# MLDR187 register map
File version: 1.3
CPU: MLDR178, little endian
Registers are 32-bit, read-write, no defined reset value unless marked. A register's access mark holds for its fields unless they carry their own. Offsets are from the block's base; [hi:lo] are bit positions; {n}, {i} and the like mark numbered series.

## TIMER1 — TIMER1 description
Base 0x40070000
Same registers: TIMER2 0x40078000, TIMER3 0x400D8000, TIMER4 0x400E0000
0x00 CNT — CNT description
0x04 PSG — PSG description
  [15:0] PSG
0x08 ARR — ARR description
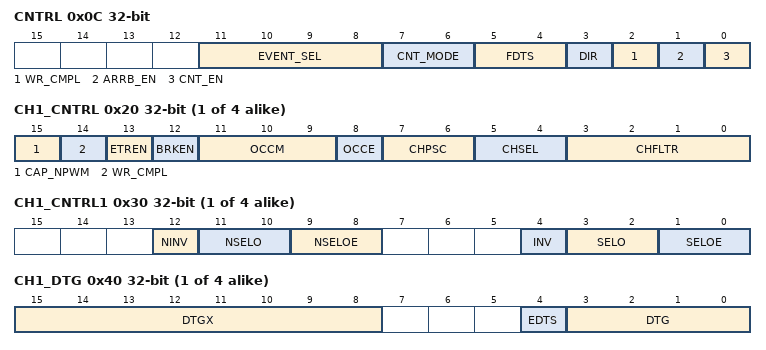
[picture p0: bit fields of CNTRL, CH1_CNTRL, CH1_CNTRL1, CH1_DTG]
0x0C CNTRL — CNTRL description
  [11:8] EVENT_SEL — EVENT_SEL description
  [7:6] CNT_MODE — CNT_MODE description
  [5:4] FDTS — FDTS description
  [3] DIR — DIR description
  [2] WR_CMPL — WR_CMPL description
  [1] ARRB_EN — ARRB_EN description
  [0] CNT_EN — CNT_EN description
{0xC+4i} CCR{i} (i=1..4) — CCR{i} description
{0x1C+4i} CH{i}_CNTRL (i=1..4) — CH{i}_CNTRL description
  [15] CAP_NPWM — CAP_NPWM description
  [14] WR_CMPL — WR_CMPL description
  [13] ETREN — ETREN description
  [12] BRKEN — BRKEN description
  [11:9] OCCM — OCCM description
  [8] OCCE — OCCE description
  [7:6] CHPSC — CHPSC description
  [5:4] CHSEL — CHSEL description
  [3:0] CHFLTR — CHFLTR description
{0x2C+4i} CH{i}_CNTRL1 (i=1..4) — CH{i}_CNTRL1 description
  [12] NINV — NINV description
  [11:10] NSELO — NSELO description
  [9:8] NSELOE — NSELOE description
  [4] INV — INV description
  [3:2] SELO — SELO description
  [1:0] SELOE — SELOE description
{0x3C+4i} CH{i}_DTG (i=1..4) — CH{i}_DTG description
  [15:8] DTGX — DTGX description
  [4] EDTS — EDTS description
  [3:0] DTG — DTG description
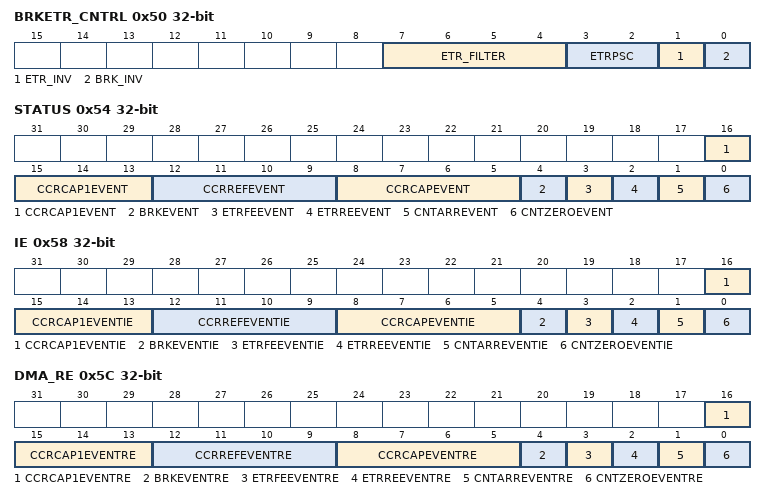
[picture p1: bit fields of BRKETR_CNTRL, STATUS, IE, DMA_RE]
0x50 BRKETR_CNTRL — BRKETR_CNTRL description
  [7:4] ETR_FILTER — ETR_FILTER description
  [3:2] ETRPSC — ETRPSC description
  [1] ETR_INV — ETR_INV description
  [0] BRK_INV — BRK_INV description
0x54 STATUS — STATUS description
  [16:13] CCRCAP1EVENT — CCRCAP1EVENT description
  [12:9] CCRREFEVENT — CCRREFEVENT description
  [8:5] CCRCAPEVENT — CCRCAPEVENT description
  [4] BRKEVENT — BRKEVENT description
  [3] ETRFEEVENT — ETRFEEVENT description
  [2] ETRREEVENT — ETRREEVENT description
  [1] CNTARREVENT — CNTARREVENT description
  [0] CNTZEROEVENT — CNTZEROEVENT description
0x58 IE — IE description
  [16:13] CCRCAP1EVENTIE — CCRCAP1EVENTIE description
  [12:9] CCRREFEVENTIE — CCRREFEVENTIE description
  [8:5] CCRCAPEVENTIE — CCRCAPEVENTIE description
  [4] BRKEVENTIE — BRKEVENTIE description
  [3] ETRFEEVENTIE — ETRFEEVENTIE description
  [2] ETRREEVENTIE — ETRREEVENTIE description
  [1] CNTARREVENTIE — CNTARREVENTIE description
  [0] CNTZEROEVENTIE — CNTZEROEVENTIE description
0x5C DMA_RE — DMA_RE description
  [16:13] CCRCAP1EVENTRE — CCRCAP1EVENTRE description
  [12:9] CCRREFEVENTRE — CCRREFEVENTRE description
  [8:5] CCRCAPEVENTRE — CCRCAPEVENTRE description
  [4] BRKEVENTRE — BRKEVENTRE description
  [3] ETRFEEVENTRE — ETRFEEVENTRE description
  [2] ETRREEVENTRE — ETRREEVENTRE description
  [1] CNTARREVENTRE — CNTARREVENTRE description
  [0] CNTZEROEVENTRE — CNTZEROEVENTRE description
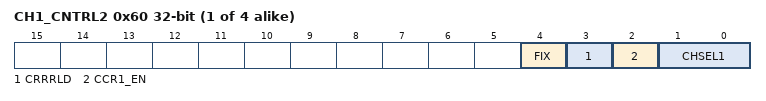
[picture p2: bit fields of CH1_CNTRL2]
{0x5C+4i} CH{i}_CNTRL2 (i=1..4) — CH{i}_CNTRL2 description
  [4] FIX — FIX description
  [3] CRRRLD — CRRRLD description
  [2] CCR1_EN — CCR1_EN description
  [1:0] CHSEL1 — CHSEL1 description
0x70 CCR11 — CCR11 description
0x74 CCR21 — CCR21 description
0x78 CCR31 — CCR31 description
0x7C CCR41 — CCR41 description
{0x7C+4i} DMA_RECH{i} (i=1..4) — DMA_RECH{i} description

## I2C — I2C description
Base 0x40030000
0x00 PRL — PRL description
  [7:0] PR — PR description
0x04 PRH — PRH description
  [7:0] PR — PR description
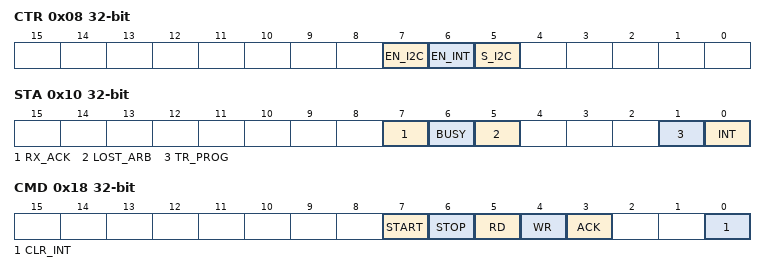
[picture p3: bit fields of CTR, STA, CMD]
0x08 CTR — CTR description
  [7] EN_I2C — EN_I2C description
  [6] EN_INT — EN_INT description
  [5] S_I2C — S_I2C description
0x0C RXD — RXD description
  [7:0] RXD
0x10 STA — STA description
  [7] RX_ACK — RX_ACK description
  [6] BUSY — BUSY description
  [5] LOST_ARB — LOST_ARB description
  [1] TR_PROG — TR_PROG description
  [0] INT — INT description
0x14 TXD — TXD description
  [7:0] TXD
0x18 CMD — CMD description
  [7] START — START description
  [6] STOP — STOP description
  [5] RD — RD description
  [4] WR — WR description
  [3] ACK — ACK description
  [0] CLR_INT — CLR_INT description
